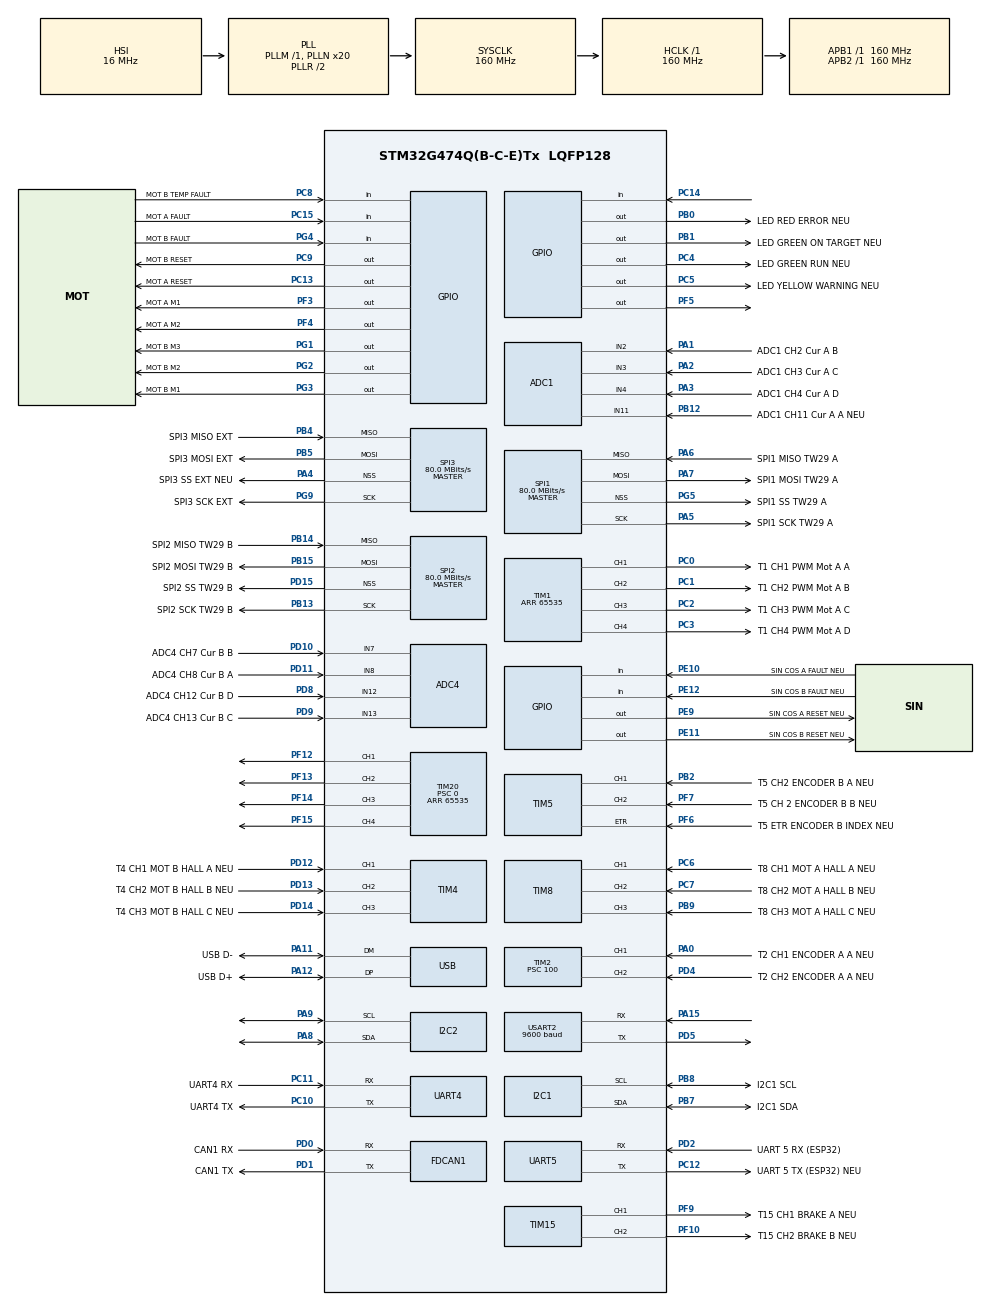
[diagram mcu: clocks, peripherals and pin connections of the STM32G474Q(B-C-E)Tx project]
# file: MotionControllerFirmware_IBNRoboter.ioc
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ADC1.Channel-0\#ChannelRegularConversion=ADC_CHANNEL_2
ADC1.NbrOfConversionFlag=1
ADC1.OffsetNumber-0\#ChannelRegularConversion=ADC_OFFSET_NONE
ADC1.Rank-0\#ChannelRegularConversion=1
ADC1.SamplingTime-0\#ChannelRegularConversion=ADC_SAMPLETIME_2CYCLES_5
ADC1.master=1
ADC4.Channel-1\#ChannelRegularConversion=ADC_CHANNEL_12
ADC4.NbrOfConversionFlag=1
ADC4.OffsetNumber-1\#ChannelRegularConversion=ADC_OFFSET_NONE
ADC4.Rank-1\#ChannelRegularConversion=1
ADC4.SamplingTime-1\#ChannelRegularConversion=ADC_SAMPLETIME_2CYCLES_5
FDCAN1.AutoRetransmission=ENABLE
FDCAN1.CalculateBaudRateNominal=4000000
FDCAN1.CalculateTimeBitNominal=250
FDCAN1.CalculateTimeQuantumNominal=12.5
FDCAN1.DataPrescaler=17
FDCAN1.DataSyncJumpWidth=9
FDCAN1.DataTimeSeg1=10
FDCAN1.DataTimeSeg2=9
FDCAN1.FrameFormat=FDCAN_FRAME_FD_NO_BRS
FDCAN1.Mode=FDCAN_MODE_EXTERNAL_LOOPBACK
FDCAN1.NominalPrescaler=2
FDCAN1.NominalSyncJumpWidth=3
FDCAN1.NominalTimeSeg1=16
FDCAN1.NominalTimeSeg2=3
FREERTOS.Tasks01=defaultTask,24,128,StartDefaultTask,Default,NULL,Dynamic,NULL,NULL;IBNblinkLED,8,128,startIBNBlinkLED,Default,NULL,Dynamic,NULL,NULL;IBNstepper,24,128,startIBNStepper,Default,NULL,Dynamic,NULL,NULL;IBNerrorHandler,24,128,startIBNerrorHandler,Default,NULL,Dynamic,NULL,NULL
FREERTOS.configTOTAL_HEAP_SIZE=10000
I2C1.Timing=0x30D29DE4
I2C2.Timing=0x30D29DE4
Mcu.Family=STM32G4
Mcu.Name=STM32G474Q(B-C-E)Tx
Mcu.Package=LQFP128
NVIC.FDCAN1_IT0_IRQn=true\:5\:0\:false\:false\:true\:true\:true\:true\:true
NVIC.PriorityGroup=NVIC_PRIORITYGROUP_4
NVIC.TIM1_TRG_COM_TIM17_IRQn=true\:5\:0\:true\:false\:true\:true\:true\:true\:true
NVIC.TIM3_IRQn=true\:5\:0\:true\:false\:true\:true\:true\:true\:true
PA0.GPIO_Label=T2 CH1 ENCODER A A NEU
PA0.Signal=S_TIM2_CH1
PA1.GPIO_Label=ADC1 CH2 Cur A B
PA1.Mode=IN2-Single-Ended
PA1.Signal=ADC1_IN2
PA11.GPIO_Label=USB D-
PA11.Mode=Device
PA11.Signal=USB_DM
PA12.GPIO_Label=USB D+
PA12.Mode=Device
PA12.Signal=USB_DP
PA13.GPIO_Label=SWD SWDIO
PA13.Mode=Serial_Wire
PA13.Signal=SYS_JTMS-SWDIO
PA14.GPIO_Label=SWD SWCLK
PA14.Mode=Serial_Wire
PA14.Signal=SYS_JTCK-SWCLK
PA15.Mode=Asynchronous
PA15.Signal=USART2_RX
PA2.GPIO_Label=ADC1 CH3 Cur A C
PA2.Mode=IN3-Single-Ended
PA2.Signal=ADC1_IN3
PA3.GPIO_Label=ADC1 CH4 Cur A D
PA3.Mode=IN4-Single-Ended
PA3.Signal=ADC1_IN4
PA4.GPIO_Label=SPI3 SS EXT NEU
PA4.Mode=NSS_Signal_Hard_Output
PA4.Signal=SPI3_NSS
PA5.GPIO_Label=SPI1 SCK TW29 A
PA5.Mode=Full_Duplex_Master
PA5.Signal=SPI1_SCK
PA6.GPIO_Label=SPI1 MISO TW29 A
PA6.Mode=Full_Duplex_Master
PA6.Signal=SPI1_MISO
PA7.GPIO_Label=SPI1 MOSI TW29 A
PA7.Mode=Full_Duplex_Master
PA7.Signal=SPI1_MOSI
PA8.Mode=I2C
PA8.Signal=I2C2_SDA
PA9.Mode=I2C
PA9.Signal=I2C2_SCL
PB0.GPIO_Label=LED RED ERROR NEU
PB0.Signal=GPIO_Output
PB1.GPIO_Label=LED GREEN ON TARGET NEU
PB1.Signal=GPIO_Output
PB12.GPIO_Label=ADC1 CH11 Cur A A NEU
PB12.Mode=IN11-Single-Ended
PB12.Signal=ADC1_IN11
PB13.GPIO_Label=SPI2 SCK TW29 B
PB13.Mode=Full_Duplex_Master
PB13.Signal=SPI2_SCK
PB14.GPIO_Label=SPI2 MISO TW29 B
PB14.Mode=Full_Duplex_Master
PB14.Signal=SPI2_MISO
PB15.GPIO_Label=SPI2 MOSI TW29 B
PB15.Mode=Full_Duplex_Master
PB15.Signal=SPI2_MOSI
PB2.GPIO_Label=T5 CH2 ENCODER B A NEU
PB2.Signal=S_TIM5_CH1
PB3.Signal=SYS_JTDO-SWO
PB4.GPIO_Label=SPI3 MISO EXT
PB4.Mode=Full_Duplex_Master
PB4.Signal=SPI3_MISO
PB5.GPIO_Label=SPI3 MOSI EXT
PB5.Mode=Full_Duplex_Master
PB5.Signal=SPI3_MOSI
PB7.GPIO_Label=I2C1 SDA
PB7.Mode=I2C
PB7.Signal=I2C1_SDA
PB8-BOOT0.GPIO_Label=I2C1 SCL
PB8-BOOT0.Mode=I2C
PB8-BOOT0.Signal=I2C1_SCL
PB9.GPIO_Label=T8 CH3 MOT A HALL C NEU
PB9.Signal=S_TIM8_CH3
PC0.GPIO_Label=T1 CH1 PWM Mot A A
PC0.Signal=S_TIM1_CH1
PC1.GPIO_Label=T1 CH2 PWM Mot A B
PC1.Signal=S_TIM1_CH2
PC10.GPIO_Label=UART4 TX
PC10.Mode=Asynchronous
PC10.Signal=UART4_TX
PC11.GPIO_Label=UART4 RX
PC11.Mode=Asynchronous
PC11.Signal=UART4_RX
PC12.GPIO_Label=UART 5 TX (ESP32) NEU
PC12.Mode=Asynchronous
PC12.Signal=UART5_TX
PC13.GPIO_Label=MOT A RESET
PC13.Signal=GPIO_Output
PC14-OSC32_IN.Signal=GPIO_Input
PC15-OSC32_OUT.GPIO_Label=MOT A FAULT
PC15-OSC32_OUT.Signal=GPIO_Input
PC2.GPIO_Label=T1 CH3 PWM Mot A C
PC2.Signal=S_TIM1_CH3
PC3.GPIO_Label=T1 CH4 PWM Mot A D
PC3.Signal=S_TIM1_CH4
PC4.GPIO_Label=LED GREEN RUN NEU
PC4.Signal=GPIO_Output
PC5.GPIO_Label=LED YELLOW WARNING NEU
PC5.Signal=GPIO_Output
PC6.GPIO_Label=T8 CH1 MOT A HALL A NEU
PC6.Signal=S_TIM8_CH1
PC7.GPIO_Label=T8 CH2 MOT A HALL B NEU
PC7.Signal=S_TIM8_CH2
PC8.GPIO_Label=MOT B TEMP FAULT
PC8.Signal=GPIO_Input
PC9.GPIO_Label=MOT B RESET
PC9.Signal=GPIO_Output
PD0.GPIO_Label=CAN1 RX
PD0.Mode=FDCAN_Activate
PD0.Signal=FDCAN1_RX
PD1.GPIO_Label=CAN1 TX
PD1.Mode=FDCAN_Activate
PD1.Signal=FDCAN1_TX
PD10.GPIO_Label=ADC4 CH7 Cur B B
PD10.Mode=IN7-Single-Ended
PD10.Signal=ADC4_IN7
PD11.GPIO_Label=ADC4 CH8 Cur B A
PD11.Mode=IN8-Single-Ended
PD11.Signal=ADC4_IN8
PD12.GPIO_Label=T4 CH1 MOT B HALL A NEU
PD12.Signal=S_TIM4_CH1
PD13.GPIO_Label=T4 CH2 MOT B HALL B NEU
PD13.Signal=S_TIM4_CH2
PD14.GPIO_Label=T4 CH3 MOT B HALL C NEU
PD14.Signal=S_TIM4_CH3
PD15.GPIO_Label=SPI2 SS TW29 B
PD15.Mode=NSS_Signal_Hard_Output
PD15.Signal=SPI2_NSS
PD2.GPIO_Label=UART 5 RX (ESP32)
PD2.Mode=Asynchronous
PD2.Signal=UART5_RX
PD3.Signal=S_TIM2_ETR
PD4.GPIO_Label=T2 CH2 ENCODER A A NEU
PD4.Signal=S_TIM2_CH2
PD5.Mode=Asynchronous
PD5.Signal=USART2_TX
PD8.GPIO_Label=ADC4 CH12 Cur B D
PD8.Mode=IN12-Single-Ended
PD8.Signal=ADC4_IN12
PD9.GPIO_Label=ADC4 CH13 Cur B C
PD9.Mode=IN13-Single-Ended
PD9.Signal=ADC4_IN13
PE10.GPIO_Label=SIN COS A FAULT NEU
PE10.Signal=GPIO_Input
PE11.GPIO_Label=SIN COS B RESET NEU
PE11.Signal=GPIO_Output
PE12.GPIO_Label=SIN COS B FAULT NEU
PE12.Signal=GPIO_Input
PE2.Signal=SYS_TRACECLK
PE3.Signal=SYS_TRACED0
PE4.Signal=SYS_TRACED1
PE5.Signal=SYS_TRACED2
PE6.Signal=SYS_TRACED3
PE9.GPIO_Label=SIN COS A RESET NEU
PE9.Signal=GPIO_Output
PF0-OSC_IN.GPIO_Label=HSE IN
PF0-OSC_IN.Mode=HSE-External-Oscillator
PF0-OSC_IN.Signal=RCC_OSC_IN
PF1-OSC_OUT.GPIO_Label=HSE OUT
PF1-OSC_OUT.Mode=HSE-External-Oscillator
PF1-OSC_OUT.Signal=RCC_OSC_OUT
PF10.GPIO_Label=T15 CH2 BRAKE B NEU
PF10.Signal=S_TIM15_CH2
PF12.GPIO_ModeDefaultPP=GPIO_MODE_AF_PP
PF12.GPIO_PuPd=GPIO_NOPULL
PF12.GPIO_Speed=GPIO_SPEED_FREQ_LOW
PF12.Signal=S_TIM20_CH1
PF13.GPIO_ModeDefaultPP=GPIO_MODE_AF_PP
PF13.GPIO_PuPd=GPIO_NOPULL
PF13.GPIO_Speed=GPIO_SPEED_FREQ_LOW
PF13.Signal=S_TIM20_CH2
PF14.GPIO_ModeDefaultPP=GPIO_MODE_AF_PP
PF14.GPIO_PuPd=GPIO_NOPULL
PF14.GPIO_Speed=GPIO_SPEED_FREQ_LOW
PF14.Signal=S_TIM20_CH3
PF15.GPIO_ModeDefaultPP=GPIO_MODE_AF_PP
PF15.GPIO_PuPd=GPIO_NOPULL
PF15.GPIO_Speed=GPIO_SPEED_FREQ_LOW
PF15.Signal=S_TIM20_CH4
PF3.GPIO_Label=MOT A M1
PF3.Signal=GPIO_Output
PF4.GPIO_Label=MOT A M2
PF4.Signal=GPIO_Output
PF5.Signal=GPIO_Output
PF6.GPIO_Label=T5 ETR ENCODER B INDEX NEU
PF6.Signal=S_TIM5_ETR
PF7.GPIO_Label=T5 CH 2 ENCODER B B NEU
PF7.Signal=S_TIM5_CH2
PF9.GPIO_Label=T15 CH1 BRAKE A NEU
PF9.Signal=S_TIM15_CH1
PG1.GPIO_Label=MOT B M3
PG1.Signal=GPIO_Output
PG2.GPIO_Label=MOT B M2
PG2.Signal=GPIO_Output
PG3.GPIO_Label=MOT B M1
PG3.Signal=GPIO_Output
PG4.GPIO_Label=MOT B FAULT
PG4.Signal=GPIO_Input
PG5.GPIO_Label=SPI1 SS TW29 A
PG5.Mode=NSS_Signal_Hard_Output
PG5.Signal=SPI1_NSS
PG9.GPIO_Label=SPI3 SCK EXT
PG9.Mode=Full_Duplex_Master
PG9.Signal=SPI3_SCK
ProjectManager.HeapSize=0x200
ProjectManager.StackSize=0x400
ProjectManager.TargetToolchain=STM32CubeIDE
RCC.ADC12Freq_Value=160000000
RCC.ADC345Freq_Value=160000000
RCC.AHBFreq_Value=160000000
RCC.APB1Freq_Value=160000000
RCC.APB1TimFreq_Value=160000000
RCC.APB2Freq_Value=160000000
RCC.APB2TimFreq_Value=160000000
RCC.CK48CLockSelection=RCC_USBCLKSOURCE_HSI48
RCC.CortexFreq_Value=160000000
RCC.EXTERNAL_CLOCK_VALUE=12288000
RCC.HCLKFreq_Value=160000000
RCC.HSE_VALUE=48000000
RCC.HSI48_VALUE=48000000
RCC.HSI_VALUE=16000000
RCC.LSE_VALUE=32768
RCC.PLLN=20
RCC.PLLQ=RCC_PLLQ_DIV4
RCC.SYSCLKFreq_VALUE=160000000
RCC.SYSCLKSource=RCC_SYSCLKSOURCE_PLLCLK
RCC.USBFreq_Value=48000000
RCC.VCOOutputFreq_Value=320000000
SH.S_TIM15_CH1.0=TIM15_CH1,Output Compare1 CH1
SH.S_TIM15_CH2.0=TIM15_CH2,Output Compare2 CH2
SH.S_TIM1_CH1.0=TIM1_CH1,PWM Generation1 CH1
SH.S_TIM1_CH2.0=TIM1_CH2,PWM Generation2 CH2
SH.S_TIM1_CH3.0=TIM1_CH3,PWM Generation3 CH3
SH.S_TIM1_CH4.0=TIM1_CH4,PWM Generation4 CH4
SH.S_TIM20_CH1.0=TIM20_CH1,PWM Generation1 CH1
SH.S_TIM20_CH2.0=TIM20_CH2,PWM Generation2 CH2
SH.S_TIM20_CH3.0=TIM20_CH3,PWM Generation3 CH3
SH.S_TIM20_CH4.0=TIM20_CH4,PWM Generation4 CH4
SH.S_TIM2_CH1.0=TIM2_CH1,Encoder_Interface
SH.S_TIM2_CH2.0=TIM2_CH2,Encoder_Interface
SH.S_TIM2_ETR.0=TIM2_ETR
SH.S_TIM4_CH1.0=TIM4_CH1,Xored_Inputs_Hall_Sensor_Interface
SH.S_TIM4_CH2.0=TIM4_CH2,Xored_Inputs_Hall_Sensor_Interface
SH.S_TIM4_CH3.0=TIM4_CH3,Xored_Inputs_Hall_Sensor_Interface
SH.S_TIM5_CH1.0=TIM5_CH1,Encoder_Interface_w_index
SH.S_TIM5_CH2.0=TIM5_CH2,Encoder_Interface_w_index
SH.S_TIM5_ETR.0=TIM5_ETR,Encoder_Interface_w_index
SH.S_TIM8_CH1.0=TIM8_CH1,Xored_Inputs_Hall_Sensor_Interface
SH.S_TIM8_CH2.0=TIM8_CH2,Xored_Inputs_Hall_Sensor_Interface
SH.S_TIM8_CH3.0=TIM8_CH3,Xored_Inputs_Hall_Sensor_Interface
SPI1.BaudRatePrescaler=SPI_BAUDRATEPRESCALER_2
SPI1.CalculateBaudRate=80.0 MBits/s
SPI1.Direction=SPI_DIRECTION_2LINES
SPI1.Mode=SPI_MODE_MASTER
SPI1.VirtualNSS=VM_NSSHARD
SPI1.VirtualType=VM_MASTER
SPI2.BaudRatePrescaler=SPI_BAUDRATEPRESCALER_2
SPI2.CalculateBaudRate=80.0 MBits/s
SPI2.Direction=SPI_DIRECTION_2LINES
SPI2.Mode=SPI_MODE_MASTER
SPI2.VirtualNSS=VM_NSSHARD
SPI2.VirtualType=VM_MASTER
SPI3.BaudRatePrescaler=SPI_BAUDRATEPRESCALER_2
SPI3.CalculateBaudRate=80.0 MBits/s
SPI3.Direction=SPI_DIRECTION_2LINES
SPI3.Mode=SPI_MODE_MASTER
SPI3.VirtualNSS=VM_NSSHARD
SPI3.VirtualType=VM_MASTER
TIM1.AutoReloadPreload=TIM_AUTORELOAD_PRELOAD_DISABLE
TIM1.Channel-PWM\ Generation1\ CH1=TIM_CHANNEL_1
TIM1.Channel-PWM\ Generation2\ CH2=TIM_CHANNEL_2
TIM1.Channel-PWM\ Generation3\ CH3=TIM_CHANNEL_3
TIM1.Channel-PWM\ Generation4\ CH4=TIM_CHANNEL_4
TIM1.PeriodNoDither=65535
TIM15.Channel-Output\ Compare1\ CH1=TIM_CHANNEL_1
TIM15.Channel-Output\ Compare2\ CH2=TIM_CHANNEL_2
TIM17.AutoReloadPreload=TIM_AUTORELOAD_PRELOAD_ENABLE
TIM17.PeriodNoDither=1000
TIM17.Prescaler=16
TIM2.CounterMode=TIM_COUNTERMODE_DOWN
TIM2.EncoderMode=TIM_ENCODERMODE_TI12
TIM2.Prescaler=100
TIM20.AutoReloadPreload=TIM_AUTORELOAD_PRELOAD_ENABLE
TIM20.Channel-PWM\ Generation1\ CH1=TIM_CHANNEL_1
TIM20.Channel-PWM\ Generation2\ CH2=TIM_CHANNEL_2
TIM20.Channel-PWM\ Generation3\ CH3=TIM_CHANNEL_3
TIM20.Channel-PWM\ Generation4\ CH4=TIM_CHANNEL_4
TIM20.PeriodNoDither=65535
TIM20.Prescaler=0
TIM3.PeriodNoDither=1600
USART2.BaudRate=9600
USART2.OverrunDisableParam=ADVFEATURE_OVERRUN_DISABLE
USART2.VirtualMode-Asynchronous=VM_ASYNC
VP_FREERTOS_VS_CMSIS_V2.Mode=CMSIS_V2
VP_SYS_VS_DBSignals.Mode=DisableDeadBatterySignals
VP_TIM17_VS_ClockSourceINT.Mode=Enable_Timer
VP_TIM20_VS_ClockSourceINT.Mode=Internal
VP_TIM3_VS_ClockSourceINT.Mode=Internal
board=custom

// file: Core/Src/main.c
/* USER CODE BEGIN Header */
/**
  ******************************************************************************
  * @file           : main.c
  * @brief          : Main program body
  ******************************************************************************
  * @attention
  *
  * Copyright (c) 2025 STMicroelectronics.
  * All rights reserved.
  *
  * This software is licensed under terms that can be found in the LICENSE file
  * in the root directory of this software component.
  * If no LICENSE file comes with this software, it is provided AS-IS.
  *
  ******************************************************************************
  */
/* USER CODE END Header */
#include "main.h"
#include "cmsis_os.h"
#include "adc.h"
#include "fdcan.h"
#include "i2c.h"
#include "spi.h"
#include "tim.h"
#include "usart.h"
#include "usb.h"
#include "gpio.h"

/* USER CODE BEGIN Includes */
#include "inbetriebnahme.h"
/* USER CODE END Includes */

void SystemClock_Config(void);
void MX_FREERTOS_Init(void);

int main(void)
{

  /* MCU Configuration--------------------------------------------------------*/

  /* Reset of all peripherals, Initializes the Flash interface and the Systick. */
  HAL_Init();

  /* Configure the system clock */
  SystemClock_Config();

  /* Initialize all configured peripherals */
  MX_GPIO_Init();
  MX_ADC1_Init();
  MX_ADC4_Init();
  MX_FDCAN1_Init();
  MX_I2C1_Init();
  MX_SPI1_Init();
  MX_SPI2_Init();
  MX_SPI3_Init();
  MX_TIM2_Init();
  MX_TIM5_Init();
  MX_TIM20_Init();
  MX_UART4_Init();
  MX_USB_PCD_Init();
  MX_TIM4_Init();
  MX_TIM8_Init();
  MX_TIM15_Init();
  MX_UART5_Init();
  MX_TIM3_Init();
  MX_TIM17_Init();
  MX_USART2_UART_Init();
  MX_TIM1_Init();
  MX_I2C2_Init();
  /* USER CODE BEGIN 2 */
  SCB->VTOR = FLASH_BASE; // set adress vector table for HAL interupt
  IBN_Init();
  IBN_Stepper_Init();
  //Set_PWM_DutyCycle(TIM_CHANNEL_1, 500);
  if(0)
  {
  /* USER CODE END 2 */

  /* Init scheduler */
  osKernelInitialize();

  /* Call init function for freertos objects (in cmsis_os2.c) */
  MX_FREERTOS_Init();

  /* Start scheduler */
  osKernelStart();

  /* We should never get here as control is now taken by the scheduler */

  /* Infinite loop */
  /* USER CODE BEGIN WHILE */
  }
  HAL_TIM_Encoder_Start(&htim2, TIM_CHANNEL_ALL);

  uint8_t a;
  if (__HAL_RCC_TIM2_IS_CLK_ENABLED()) {
      a = 1;
  } else {
      a = 2;
  }
  volatile uint16_t b;
  	if (__HAL_TIM_IS_TIM_COUNTING_DOWN(&htim2)) {
  	    b = 1;
  	} else {
  	    b = 2;
  	}
  	__HAL_TIM_SET_COUNTER(&htim2, 1000);
  	volatile uint16_t encoder_value;
  while (1)
  {
	  encoder_value = __HAL_TIM_GET_COUNTER(&htim2);
    /* USER CODE END WHILE */

  }
}

void SystemClock_Config(void)
{
  RCC_OscInitTypeDef RCC_OscInitStruct = {0};
  RCC_ClkInitTypeDef RCC_ClkInitStruct = {0};

  /** Configure the main internal regulator output voltage
  */
  HAL_PWREx_ControlVoltageScaling(PWR_REGULATOR_VOLTAGE_SCALE1_BOOST);

  /** Initializes the RCC Oscillators according to the specified parameters
  * in the RCC_OscInitTypeDef structure.
  */
  RCC_OscInitStruct.OscillatorType = RCC_OSCILLATORTYPE_HSI|RCC_OSCILLATORTYPE_HSI48;
  RCC_OscInitStruct.HSIState = RCC_HSI_ON;
  RCC_OscInitStruct.HSICalibrationValue = RCC_HSICALIBRATION_DEFAULT;
  RCC_OscInitStruct.HSI48State = RCC_HSI48_ON;
  RCC_OscInitStruct.PLL.PLLState = RCC_PLL_ON;
  RCC_OscInitStruct.PLL.PLLSource = RCC_PLLSOURCE_HSI;
  RCC_OscInitStruct.PLL.PLLM = RCC_PLLM_DIV1;
  RCC_OscInitStruct.PLL.PLLN = 20;
  RCC_OscInitStruct.PLL.PLLP = RCC_PLLP_DIV2;
  RCC_OscInitStruct.PLL.PLLQ = RCC_PLLQ_DIV4;
  RCC_OscInitStruct.PLL.PLLR = RCC_PLLR_DIV2;
  if (HAL_RCC_OscConfig(&RCC_OscInitStruct) != HAL_OK)
  {
    Error_Handler();
  }

  /** Initializes the CPU, AHB and APB buses clocks
  */
  RCC_ClkInitStruct.ClockType = RCC_CLOCKTYPE_HCLK|RCC_CLOCKTYPE_SYSCLK
                              |RCC_CLOCKTYPE_PCLK1|RCC_CLOCKTYPE_PCLK2;
  RCC_ClkInitStruct.SYSCLKSource = RCC_SYSCLKSOURCE_PLLCLK;
  RCC_ClkInitStruct.AHBCLKDivider = RCC_SYSCLK_DIV1;
  RCC_ClkInitStruct.APB1CLKDivider = RCC_HCLK_DIV1;
  RCC_ClkInitStruct.APB2CLKDivider = RCC_HCLK_DIV1;

  if (HAL_RCC_ClockConfig(&RCC_ClkInitStruct, FLASH_LATENCY_4) != HAL_OK)
  {
    Error_Handler();
  }
}

void Error_Handler(void)
{
  __disable_irq();
  while (1)
  {
  }
}

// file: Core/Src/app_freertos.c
/* USER CODE BEGIN Header */
/**
  ******************************************************************************
  * File Name          : app_freertos.c
  * Description        : Code for freertos applications
  ******************************************************************************
  * @attention
  *
  * Copyright (c) 2025 STMicroelectronics.
  * All rights reserved.
  *
  * This software is licensed under terms that can be found in the LICENSE file
  * in the root directory of this software component.
  * If no LICENSE file comes with this software, it is provided AS-IS.
  *
  ******************************************************************************
  */
/* USER CODE END Header */

#include "FreeRTOS.h"
#include "task.h"
#include "main.h"
#include "cmsis_os.h"

/* USER CODE BEGIN Includes */
#include "tim.h"
/* USER CODE END Includes */

/* Definitions for defaultTask */
osThreadId_t defaultTaskHandle;
const osThreadAttr_t defaultTask_attributes = {
  .name = "defaultTask",
  .priority = (osPriority_t) osPriorityNormal,
  .stack_size = 128 * 4
};
/* Definitions for IBNblinkLED */
osThreadId_t IBNblinkLEDHandle;
const osThreadAttr_t IBNblinkLED_attributes = {
  .name = "IBNblinkLED",
  .priority = (osPriority_t) osPriorityLow,
  .stack_size = 128 * 4
};
/* Definitions for IBNstepper */
osThreadId_t IBNstepperHandle;
const osThreadAttr_t IBNstepper_attributes = {
  .name = "IBNstepper",
  .priority = (osPriority_t) osPriorityNormal,
  .stack_size = 128 * 4
};
/* Definitions for IBNerrorHandler */
osThreadId_t IBNerrorHandlerHandle;
const osThreadAttr_t IBNerrorHandler_attributes = {
  .name = "IBNerrorHandler",
  .priority = (osPriority_t) osPriorityNormal,
  .stack_size = 128 * 4
};

void StartDefaultTask(void *argument);
void startIBNBlinkLED(void *argument);
void startIBNStepper(void *argument);
void startIBNerrorHandler(void *argument);

void MX_FREERTOS_Init(void); /* (MISRA C 2004 rule 8.1) */

void MX_FREERTOS_Init(void) {

  /* Create the thread(s) */
  /* creation of defaultTask */
  defaultTaskHandle = osThreadNew(StartDefaultTask, NULL, &defaultTask_attributes);

  /* creation of IBNblinkLED */
  IBNblinkLEDHandle = osThreadNew(startIBNBlinkLED, NULL, &IBNblinkLED_attributes);

  /* creation of IBNstepper */
  IBNstepperHandle = osThreadNew(startIBNStepper, NULL, &IBNstepper_attributes);

  /* creation of IBNerrorHandler */
  IBNerrorHandlerHandle = osThreadNew(startIBNerrorHandler, NULL, &IBNerrorHandler_attributes);

}

void StartDefaultTask(void *argument)
{
  for(;;)
  {
    osDelay(1);
  }
}

void startIBNBlinkLED(void *argument)
{
  /* USER CODE BEGIN startIBNBlinkLED */
  /* Infinite loop */
  for(;;)
  {
	HAL_GPIO_TogglePin(GPIOC, GPIO_PIN_4);
    osDelay(500);
  }
  /* USER CODE END startIBNBlinkLED */
}

void startIBNStepper(void *argument)
{
  /* USER CODE BEGIN startIBNStepper */
  /* Infinite loop */

  for(;;)
  {
	  /*uint8_t error = IBN_Check_Errors();  // Prüfe Überhitzung/Fehler
	  if (error == 0) {
		  IBN_Step(720.0, 'A');  // Motor dreht sich in einer Schleife
		  osDelay(5);
	  } else if (error == 1) {
		  // Überhitzung erkannt
		  HAL_GPIO_WritePin(GPIOC, GPIO_PIN_13, GPIO_PIN_RESET);  // Treiber deaktivieren
		 // while (1);  // Stoppe das Programm
	  } else if (error == 2) {
		  // Fehler erkannt
		  HAL_GPIO_WritePin(GPIOC, GPIO_PIN_13, GPIO_PIN_RESET);  // Treiber deaktivieren
		 // while (1);  // Stoppe das Programm
	  }*/
	  volatile uint16_t encoder_value;
	  encoder_value = __HAL_TIM_GET_COUNTER(&htim2);

    osDelay(1);
  }
  /* USER CODE END startIBNStepper */
}

void startIBNerrorHandler(void *argument)
{
  /* USER CODE BEGIN startIBNerrorHandler */
  /* Infinite loop */
  for(;;)
  {
	  uint8_t error = IBN_Check_Errors();
	  if ((error == 1)|(error == 2))
	  {
		  HAL_GPIO_WritePin(GPIOB, GPIO_PIN_1, GPIO_PIN_SET);
	  }
	  else
	  {
		  HAL_GPIO_WritePin(GPIOB, GPIO_PIN_1, GPIO_PIN_RESET);
	  }
    osDelay(1000);
  }
  /* USER CODE END startIBNerrorHandler */
}
